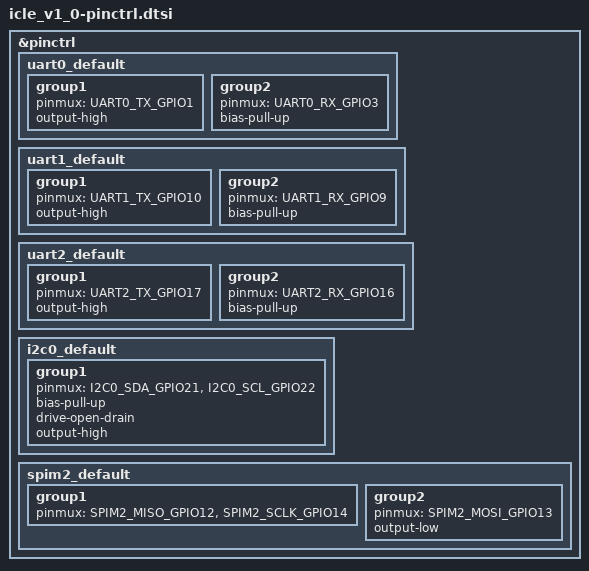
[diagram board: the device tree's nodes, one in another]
/*
 * SPDX-License-Identifier: Apache-2.0
 * CoreKinect ICLE v1.0 Pin Control
 *
 * GPIO Assignments from schematic:
 *   MUX0      = GPIO15
 *   MUX1      = GPIO2
 *   MUX2      = GPIO23
 *   PFET_GATE = GPIO19
 *   ADC_INH   = GPIO32
 *   ADC       = GPIO36 (ADC1_CH0)
 *   I2C SDA   = GPIO21
 *   I2C SCL   = GPIO22
 *   UART0 TX  = GPIO1  (console via CP2102N)
 *   UART0 RX  = GPIO3
 *   UART1 TX  = GPIO10 (DUT UART 1)
 *   UART1 RX  = GPIO9
 *   UART2 TX  = GPIO17 (DUT UART 2)
 *   UART2 RX  = GPIO16
 *   SD CLK    = GPIO14
 *   SD MOSI   = GPIO13
 *   SD MISO   = GPIO12
 *   SD CS     = GPIO5
 */

#include <zephyr/dt-bindings/pinctrl/esp-pinctrl-common.h>
#include <dt-bindings/pinctrl/esp32-pinctrl.h>
#include <zephyr/dt-bindings/pinctrl/esp32-gpio-sigmap.h>

&pinctrl {

	uart0_default: uart0_default {
		group1 {
			pinmux = <UART0_TX_GPIO1>;
			output-high;
		};
		group2 {
			pinmux = <UART0_RX_GPIO3>;
			bias-pull-up;
		};
	};

	uart1_default: uart1_default {
		group1 {
			pinmux = <UART1_TX_GPIO10>;
			output-high;
		};
		group2 {
			pinmux = <UART1_RX_GPIO9>;
			bias-pull-up;
		};
	};

	uart2_default: uart2_default {
		group1 {
			pinmux = <UART2_TX_GPIO17>;
			output-high;
		};
		group2 {
			pinmux = <UART2_RX_GPIO16>;
			bias-pull-up;
		};
	};

	i2c0_default: i2c0_default {
		group1 {
			pinmux = <I2C0_SDA_GPIO21>,
				 <I2C0_SCL_GPIO22>;
			bias-pull-up;
			drive-open-drain;
			output-high;
		};
	};

	/* SPI2 (HSPI) for SD Card */
	spim2_default: spim2_default {
		group1 {
			pinmux = <SPIM2_MISO_GPIO12>,
				 <SPIM2_SCLK_GPIO14>;
		};
		group2 {
			pinmux = <SPIM2_MOSI_GPIO13>;
			output-low;
		};
	};
};
